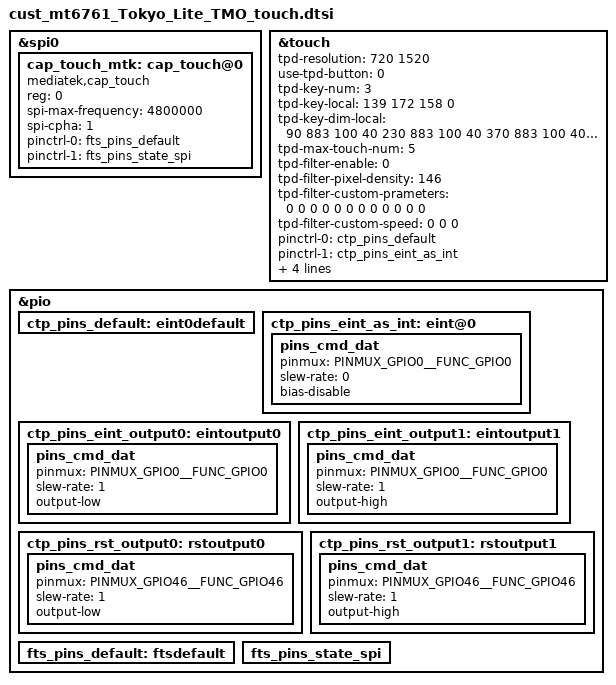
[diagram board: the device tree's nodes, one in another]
// SPDX-License-Identifier: GPL-2.0+

//Add-begin by baiwei.peng for TP porting on 2020/09/03
#include "novatek-nt36xxx-spi.dtsi"

/* TOUCH start */

//min.luo task 8205182:add 2nd lcd/tp driver 20190805  start
&spi0 {
        #address-cells = <1>;
        #size-cells = <0>;
        cap_touch_mtk: cap_touch@0 {
                compatible = "mediatek,cap_touch";
                reg = <0>;
                //begin modify by kun.zheng for task 8998289 on 2020/03/24
                //spi-max-frequency = <1000000>;
                spi-max-frequency = <4800000>;
                //end modify by kun.zheng for task 8998289 on 2020/03/24
                spi-cpha = <1>;
                //netlink-event = <31>;
                status = "okay";
                pinctrl-names = "default", "state_spi";
                pinctrl-0 = <&fts_pins_default>;
                pinctrl-1 = <&fts_pins_state_spi>;
        };
        /*
        ft8006p_ctp: fts_ts@0 {
                compatible = "focaltech,fts";
                reg = <0>;
                spi-max-frequency = <5000000>;
                spi-cpha = <1>;
                netlink-event = <31>;
                status = "okay";
                pinctrl-names = "default", "state_spi";
                pinctrl-0 = <&fts_pins_default>;
                pinctrl-1 = <&fts_pins_state_spi>; 
        };*/
};
//min.luo task 8205182:add 2nd lcd/tp driver 20190805  end

&touch {
        tpd-resolution = <720 1520>;
        use-tpd-button = <0>;
        tpd-key-num = <3>;
        tpd-key-local= <139 172 158 0>;
        tpd-key-dim-local = <90 883 100 40 230
                                 883 100 40 370 883 100 40 0 0 0 0>;
        tpd-max-touch-num = <5>;
        tpd-filter-enable = <0>;
        tpd-filter-pixel-density = <146>;
        tpd-filter-custom-prameters = <0 0 0 0 0 0 0 0 0 0 0 0>;
        tpd-filter-custom-speed = <0 0 0>;
        pinctrl-names = "default", "state_eint_as_int", "state_eint_output0",
                "state_eint_output1", "state_rst_output0", "state_rst_output1";
        pinctrl-0 = <&ctp_pins_default>;
        pinctrl-1 = <&ctp_pins_eint_as_int>;
        pinctrl-2 = <&ctp_pins_eint_output0>;
        pinctrl-3 = <&ctp_pins_eint_output1>;
        pinctrl-4 = <&ctp_pins_rst_output0>;
        pinctrl-5 = <&ctp_pins_rst_output1>;
        status = "okay";
};

&pio {
        ctp_pins_default: eint0default {
        };
        ctp_pins_eint_as_int: eint@0 {
                pins_cmd_dat {
                        pinmux = <PINMUX_GPIO0__FUNC_GPIO0>;
                        slew-rate = <0>;
                        bias-disable;
                };
        };
        ctp_pins_eint_output0: eintoutput0 {
                pins_cmd_dat {
                        pinmux = <PINMUX_GPIO0__FUNC_GPIO0>;
                        slew-rate = <1>;
                        output-low;
                };
        };
        ctp_pins_eint_output1: eintoutput1 {
                pins_cmd_dat {
                        pinmux = <PINMUX_GPIO0__FUNC_GPIO0>;
                        slew-rate = <1>;
                        output-high;
                };
        };
        ctp_pins_rst_output0: rstoutput0 {
                pins_cmd_dat {
                        pinmux = <PINMUX_GPIO46__FUNC_GPIO46>;
                        slew-rate = <1>;
                        output-low;
                };
        };
        ctp_pins_rst_output1: rstoutput1 {
                pins_cmd_dat {
                        pinmux = <PINMUX_GPIO46__FUNC_GPIO46>;
                        slew-rate = <1>;
                        output-high;
                };
        };

        fts_pins_default: ftsdefault {
        };

        fts_pins_state_spi: fts_pins_state_spi {
                /*pins_cmd_dat {
                        pinmux = <PINMUX_GPIO46__FUNC_GPIO46>;
                        slew-rate = <1>;
                        output-high;
                };*/
        };
};

/* TOUCH end */
//Add-end by baiwei.peng for TP porting on 2020/09/03
